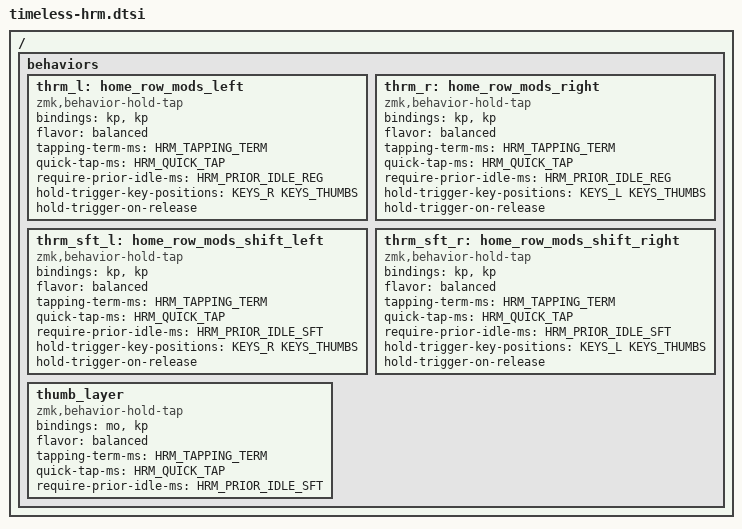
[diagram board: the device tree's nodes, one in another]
#include "zmk-helpers/key-labels/lily58.h"

#define HRM_TAPPING_TERM 300
#define HRM_QUICK_TAP 170
#define HRM_PRIOR_IDLE_REG 150
#define HRM_PRIOR_IDLE_SFT 100

#define KEYS_L LT5 LT4 LT3 LT2 LT1 LT0   LM5 LM4 LM3 LM2 LM1 LM0   LB5 LB4 LB3 LB2 LB1 LB0   LF5 LF4 LF3 LF2 LF1 LF0
#define KEYS_R RT0 RT1 RT2 RT3 RT4 RT5   RM0 RM1 RM2 RM3 RM4 RM5   RB0 RB1 RB2 RB3 RB4 RB5   RF0 RF1 RF2 RF3 RF4 RF5
#define KEYS_THUMBS LH3 LH2 LH1 LH0 LEC   REC RH0 RH1 RH2 RH3

/ {
  behaviors {
    thrm_l: home_row_mods_left {
      compatible = "zmk,behavior-hold-tap";
      #binding-cells = <2>;
      bindings = <&kp>, <&kp>;

      flavor = "balanced";
      tapping-term-ms = <HRM_TAPPING_TERM>;
      quick-tap-ms = <HRM_QUICK_TAP>;
      require-prior-idle-ms = <HRM_PRIOR_IDLE_REG>;

      hold-trigger-key-positions = <KEYS_R KEYS_THUMBS>;
      hold-trigger-on-release;
    };

    thrm_r: home_row_mods_right  {
      compatible = "zmk,behavior-hold-tap";
      #binding-cells = <2>;
      bindings = <&kp>, <&kp>;

      flavor = "balanced";
      tapping-term-ms = <HRM_TAPPING_TERM>;
      quick-tap-ms = <HRM_QUICK_TAP>;
      require-prior-idle-ms = <HRM_PRIOR_IDLE_REG>;

      hold-trigger-key-positions = <KEYS_L KEYS_THUMBS>;
      hold-trigger-on-release;
    };

    thrm_sft_l: home_row_mods_shift_left {
      compatible = "zmk,behavior-hold-tap";
      #binding-cells = <2>;
      bindings = <&kp>, <&kp>;

      flavor = "balanced";
      tapping-term-ms = <HRM_TAPPING_TERM>;
      quick-tap-ms = <HRM_QUICK_TAP>;
      require-prior-idle-ms = <HRM_PRIOR_IDLE_SFT>;

      hold-trigger-key-positions = <KEYS_R KEYS_THUMBS>;
      hold-trigger-on-release;
    };

    thrm_sft_r: home_row_mods_shift_right {
      compatible = "zmk,behavior-hold-tap";
      #binding-cells = <2>;
      bindings = <&kp>, <&kp>;

      flavor = "balanced";
      tapping-term-ms = <HRM_TAPPING_TERM>;
      quick-tap-ms = <HRM_QUICK_TAP>;
      require-prior-idle-ms = <HRM_PRIOR_IDLE_SFT>;

      hold-trigger-key-positions = <KEYS_L KEYS_THUMBS>;
      hold-trigger-on-release;
    };

    thumb_layer: thumb_layer {
      compatible = "zmk,behavior-hold-tap";
        #binding-cells = <2>;
        bindings = <&mo>, <&kp>;

      flavor = "balanced";
      tapping-term-ms = <HRM_TAPPING_TERM>;
      quick-tap-ms = <HRM_QUICK_TAP>;
      require-prior-idle-ms = <HRM_PRIOR_IDLE_SFT>;
    };
  };
};
